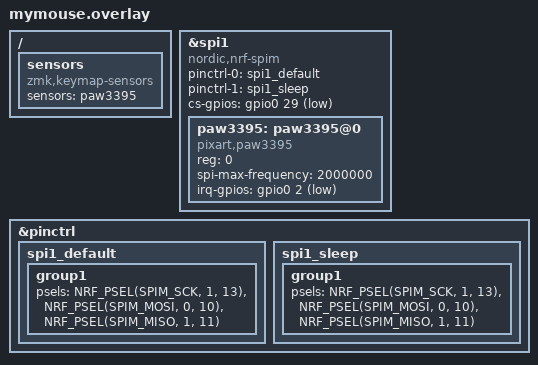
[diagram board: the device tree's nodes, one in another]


#include <dt-bindings/input/input-event-codes.h>

&spi1 {
    status = "okay";
    compatible = "nordic,nrf-spim";
    pinctrl-0 = <&spi1_default>;
    pinctrl-1 = <&spi1_sleep>;
    pinctrl-names = "default", "sleep";
    
    cs-gpios = <&gpio0 29 GPIO_ACTIVE_LOW>;
    
    paw3395: paw3395@0 {
        compatible = "pixart,paw3395";
        reg = <0>;
        spi-max-frequency = <2000000>;
        
        /* Broche d'interruption (Motion) reliée à ton capteur */
        irq-gpios = <&gpio0 2 (GPIO_ACTIVE_LOW | GPIO_PULL_UP)>;
    };
};

/* Définition des broches SPI (SCLK, MOSI, MISO, CS) - Exemple de broches sur nice!nano */
&pinctrl {
    spi1_default: spi1_default {
        group1 {
            psels = <NRF_PSEL(SPIM_SCK, 1, 13)>,  /* SCLK */
                    <NRF_PSEL(SPIM_MOSI, 0, 10)>, /* MOSI */
                    <NRF_PSEL(SPIM_MISO, 1, 11)>; /* MISO */
        };
    };

    spi1_sleep: spi1_sleep {
        group1 {
            psels = <NRF_PSEL(SPIM_SCK, 1, 13)>,
                    <NRF_PSEL(SPIM_MOSI, 0, 10)>,
                    <NRF_PSEL(SPIM_MISO, 1, 11)>;
        };
    };
};

/ {
    sensors {
        compatible = "zmk,keymap-sensors";
        sensors = <&paw3395>;
    };
};
